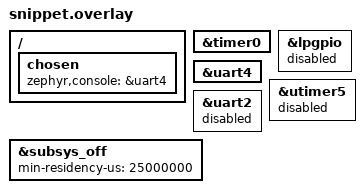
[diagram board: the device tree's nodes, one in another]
/* Copyright (C) 2026 Alif Semiconductor - All Rights Reserved.
 * Use, distribution and modification of this code is permitted under the
 * terms stated in the Alif Semiconductor Software License Agreement
 *
 * You should have received a copy of the Alif Semiconductor Software
 * License Agreement with this file. If not, please write to:
 * contact@alifsemi.com, or visit: https://alifsemi.com/license
 *
 */

&timer0 {
	status = "okay";
};

&lpgpio {
	status = "disabled";
};

&uart4 {
	status = "okay";
};

&utimer5 {
	status = "disabled";
};

&uart2 {
	status = "disabled";
};

&subsys_off {
	min-residency-us = <25000000>;
	status = "okay";
};

/ {
	chosen {
		zephyr,console = &uart4;
	};
};
